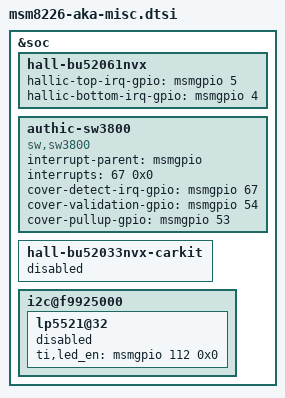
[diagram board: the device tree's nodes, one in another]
/* Copyright (c) 2012, Code Aurora Forum. All rights reserved.
 *
 * This program is free software; you can redistribute it and/or modify
 * it under the terms of the GNU General Public License version 2 and
 * only version 2 as published by the Free Software Foundation.
 *
 * This program is distributed in the hope that it will be useful,
 * but WITHOUT ANY WARRANTY; without even the implied warranty of
 * MERCHANTABILITY or FITNESS FOR A PARTICULAR PURPOSE.  See the
 * GNU General Public License for more details.
 */

&soc {
    hall-bu52061nvx {
        status = "ok";
        hallic-top-irq-gpio = <&msmgpio 5 0x00>;
        hallic-bottom-irq-gpio = <&msmgpio 4 0x00>;
    };

	authic-sw3800 {
        compatible = "sw,sw3800";
        interrupt-parent = <&msmgpio>;
        interrupts = <67 0x0>;
		cover-detect-irq-gpio = <&msmgpio 67 0x00>;
		cover-validation-gpio = <&msmgpio 54 0x00>;
		cover-pullup-gpio = <&msmgpio 53 0x00>;
        status = "ok";
    };

    hall-bu52033nvx-carkit {
        status = "disable";
    };

    i2c@f9925000 {
	lp5521@32 {
		status = "disable";
		ti,led_en = <&msmgpio 112 0x0>;
	};
    };
};
